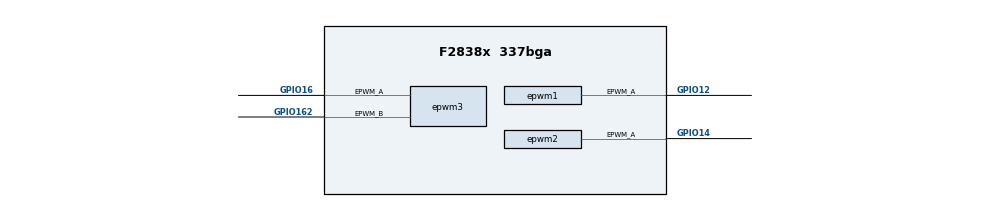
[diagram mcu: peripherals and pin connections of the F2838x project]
/**
 * @cliArgs --device "F2838x" --package "337bga" --part "F2838x_337bga" --context "CPU2" --product "C2000WARE@5.02.00.00"
 * @versions {"tool":"1.20.0+3587"}
 */

/**
 * Import the modules used in this configuration.
 */
const adc       = scripting.addModule("/driverlib/adc.js", {}, false);
const adc1      = adc.addInstance();
const cputimer  = scripting.addModule("/driverlib/cputimer.js", {}, false);
const cputimer1 = cputimer.addInstance();
const epwm      = scripting.addModule("/driverlib/epwm.js", {}, false);
const epwm1     = epwm.addInstance();
const epwm2     = epwm.addInstance();
const epwm3     = epwm.addInstance();
const flash     = scripting.addModule("/driverlib/flash.js", {}, false);
const flash1    = flash.addInstance();
const ipc       = scripting.addModule("/driverlib/ipc.js");
const sysctl    = scripting.addModule("/driverlib/sysctl.js");

/**
 * Write custom configuration values to the imported modules.
 */
adc1.$name                   = "CPU2_ADCD";
adc1.adcBase                 = "ADCD_BASE";
adc1.adcClockPrescaler       = "ADC_CLK_DIV_4_0";
adc1.enabledSOCs             = ["ADC_SOC_NUMBER0","ADC_SOC_NUMBER1"];
adc1.soc0Name                = "SOC0_DAB_VO";
adc1.soc0IndependentNameMode = true;
adc1.soc1Name                = "SOC1_DAB_VO_OVP";
adc1.soc1IndependentNameMode = true;
adc1.soc1SampleWindow        = 64;
adc1.soc0Trigger             = "ADC_TRIGGER_EPWM7_SOCA";
adc1.soc1Trigger             = "ADC_TRIGGER_EPWM7_SOCA";
adc1.soc0InputResistance     = 12;
adc1.soc0InputCapacitance    = 180;
adc1.interruptPulseMode      = "ADC_PULSE_END_OF_CONV";
adc1.enabledInts             = ["ADC_INT_NUMBER1"];
adc1.enableInterrupt1        = true;
adc1.interrupt1SOCSource     = "ADC_SOC_NUMBER1";
adc1.registerInterrupts      = ["1"];
adc1.soc0Channel             = "ADC_CH_ADCIN2";
adc1.soc0SampleWindow        = 16;
adc1.soc1Channel             = "ADC_CH_ADCIN4";
adc1.adcInt1.enableInterrupt = true;

cputimer1.$name          = "SWTIRMER";
cputimer1.cputimerBase   = "CPUTIMER1_BASE";
cputimer1.emulationMode  = "CPUTIMER_EMULATIONMODE_RUNFREE";
cputimer1.timerPrescaler = 3;
cputimer1.timerPeriod    = 50000000;
cputimer1.startTimer     = true;

epwm1.$name                  = "DAB_PWM7_PRI_AH";
epwm1.useCase                = "CUSTOM";
epwm1.useInterfacePins       = ["EPWM#A"];
epwm1.epwm.$assign           = "EPWM7";
epwm1.epwm.epwm_aPin.$assign = "GPIO12";

epwm2.$name                  = "DAB_PWM8_PRI_AL";
epwm2.useCase                = "CUSTOM";
epwm2.useInterfacePins       = ["EPWM#A"];
epwm2.epwm.$assign           = "EPWM8";
epwm2.epwm.epwm_aPin.$assign = "GPIO14";

epwm3.$name                  = "DAB_PWM9_2ND";
epwm3.epwm.$assign           = "EPWM9";
epwm3.epwm.epwm_aPin.$assign = "GPIO16";
epwm3.epwm.epwm_bPin.$assign = "GPIO162";

flash1.$name = "FMC_CPU2";

ipc.ipcRegisterFlag = ["IPC_FLAG31"];
ipc.flagHandler31   = "IPC_SYNC";

sysctl.enable_SYSCTL_PERIPH_CLK_TBCLKSYNC = true;
